AUTOSAR XML (schema 4-0-3)
package /ComponentTypes
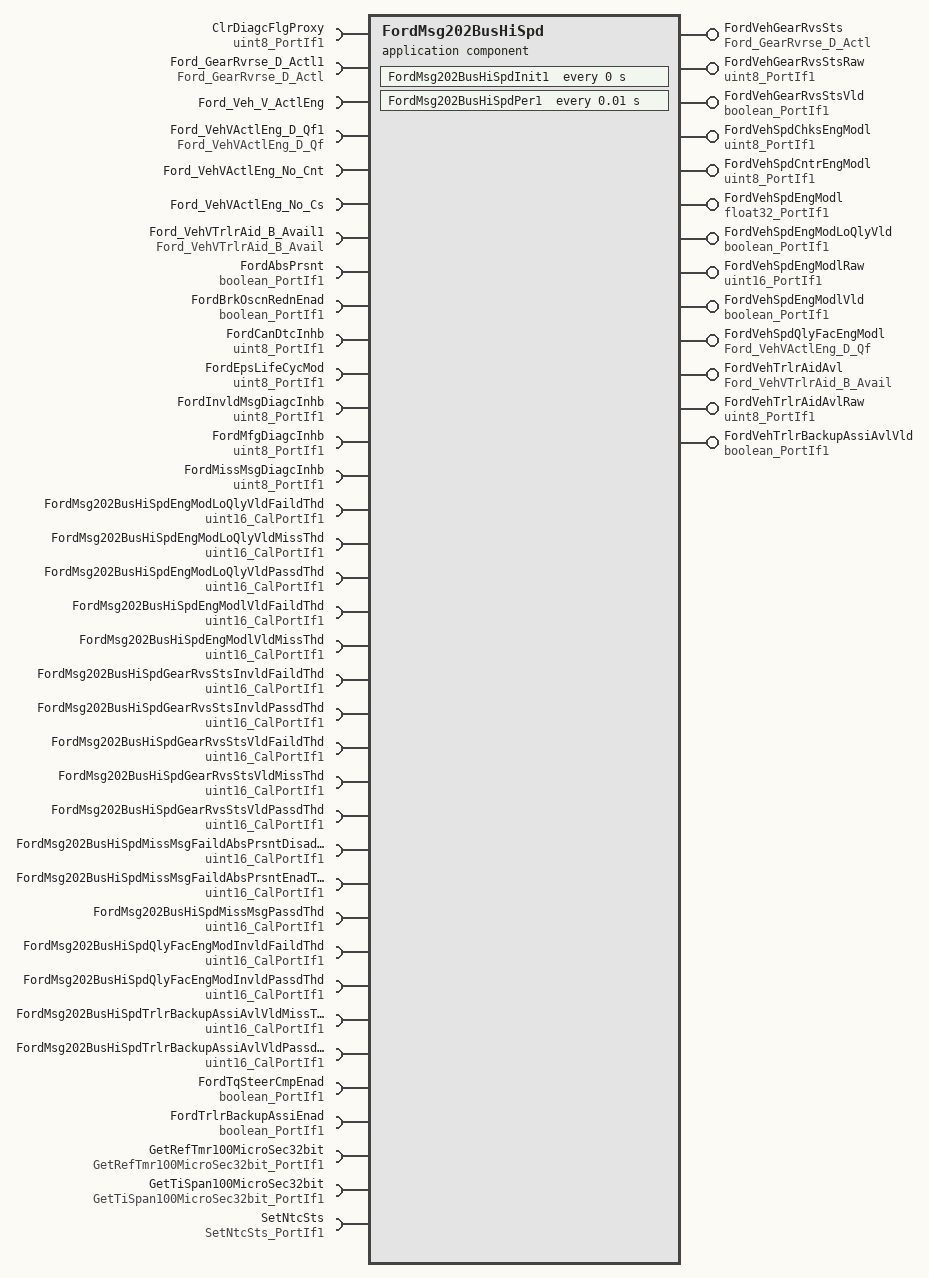
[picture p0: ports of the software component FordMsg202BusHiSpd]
  application sw component type FordMsg202BusHiSpd
    13 x provide port:
      FordVehGearRvsSts: nonqueued-sender-com-spec{data-element=Ford_GearRvrse_D_Actl, init-value=7}, provided-interface=Ford_GearRvrse_D_Actl
      FordVehGearRvsStsRaw: nonqueued-sender-com-spec{data-element=Val, init-value=7}, provided-interface=uint8_PortIf1
      FordVehGearRvsStsVld: nonqueued-sender-com-spec{data-element=Logl, init-value=0}, provided-interface=boolean_PortIf1
      FordVehSpdChksEngModl: nonqueued-sender-com-spec{data-element=Val, init-value=0}, provided-interface=uint8_PortIf1
      FordVehSpdCntrEngModl: nonqueued-sender-com-spec{data-element=Val, init-value=0}, provided-interface=uint8_PortIf1
      FordVehSpdEngModl: nonqueued-sender-com-spec{data-element=Val, init-value=0}, provided-interface=float32_PortIf1
      FordVehSpdEngModLoQlyVld: nonqueued-sender-com-spec{data-element=Logl, init-value=0}, provided-interface=boolean_PortIf1
      FordVehSpdEngModlRaw: nonqueued-sender-com-spec{data-element=Val, init-value=0}, provided-interface=uint16_PortIf1
      FordVehSpdEngModlVld: nonqueued-sender-com-spec{data-element=Logl, init-value=0}, provided-interface=boolean_PortIf1
      FordVehSpdQlyFacEngModl: nonqueued-sender-com-spec{data-element=Ford_VehVActlEng_D_Qf, init-value=0}, provided-interface=Ford_VehVActlEng_D_Qf
      FordVehTrlrAidAvl: nonqueued-sender-com-spec{data-element=Ford_VehVTrlrAid_B_Avail, init-value=0}, provided-interface=Ford_VehVTrlrAid_B_Avail
      FordVehTrlrAidAvlRaw: nonqueued-sender-com-spec{data-element=Val, init-value=0}, provided-interface=uint8_PortIf1
      FordVehTrlrBackupAssiAvlVld: nonqueued-sender-com-spec{data-element=Logl, init-value=0}, provided-interface=boolean_PortIf1
    36 x require port:
      ClrDiagcFlgProxy: nonqueued-receiver-com-spec{data-element=Val, filter=data-filter-type=ALWAYS, init-value=0}, required-interface=uint8_PortIf1
      Ford_GearRvrse_D_Actl1: nonqueued-receiver-com-spec{data-element=Ford_GearRvrse_D_Actl, filter=data-filter-type=ALWAYS, init-value=7}, required-interface=Ford_GearRvrse_D_Actl
      Ford_Veh_V_ActlEng: nonqueued-receiver-com-spec{data-element=Ford_Veh_V_ActlEng, filter=data-filter-type=ALWAYS, init-value=0}, required-interface=Ford_Veh_V_ActlEng
      Ford_VehVActlEng_D_Qf1: nonqueued-receiver-com-spec{data-element=Ford_VehVActlEng_D_Qf, filter=data-filter-type=ALWAYS, init-value=0}, required-interface=Ford_VehVActlEng_D_Qf
      Ford_VehVActlEng_No_Cnt: nonqueued-receiver-com-spec{data-element=Ford_VehVActlEng_No_Cnt, filter=data-filter-type=ALWAYS, init-value=0}, required-interface=Ford_VehVActlEng_No_Cnt
      Ford_VehVActlEng_No_Cs: nonqueued-receiver-com-spec{data-element=Ford_VehVActlEng_No_Cs, filter=data-filter-type=ALWAYS, init-value=0}, required-interface=Ford_VehVActlEng_No_Cs
      Ford_VehVTrlrAid_B_Avail1: nonqueued-receiver-com-spec{data-element=Ford_VehVTrlrAid_B_Avail, filter=data-filter-type=ALWAYS, init-value=0}, required-interface=Ford_VehVTrlrAid_B_Avail
      FordAbsPrsnt: nonqueued-receiver-com-spec{data-element=Logl, filter=data-filter-type=ALWAYS, init-value=0}, required-interface=boolean_PortIf1
      FordBrkOscnRednEnad: nonqueued-receiver-com-spec{data-element=Logl, filter=data-filter-type=ALWAYS, init-value=0}, required-interface=boolean_PortIf1
      FordCanDtcInhb: nonqueued-receiver-com-spec{data-element=Val, filter=data-filter-type=ALWAYS, init-value=1}, required-interface=uint8_PortIf1
      FordEpsLifeCycMod: nonqueued-receiver-com-spec{data-element=Val, filter=data-filter-type=ALWAYS, init-value=0}, required-interface=uint8_PortIf1
      FordInvldMsgDiagcInhb: nonqueued-receiver-com-spec{data-element=Val, filter=data-filter-type=ALWAYS, init-value=0}, required-interface=uint8_PortIf1
      FordMfgDiagcInhb: nonqueued-receiver-com-spec{data-element=Val, filter=data-filter-type=ALWAYS, init-value=0}, required-interface=uint8_PortIf1
      FordMissMsgDiagcInhb: nonqueued-receiver-com-spec{data-element=Val, filter=data-filter-type=ALWAYS, init-value=0}, required-interface=uint8_PortIf1
      FordMsg202BusHiSpdEngModLoQlyVldFaildThd: parameter-require-com-spec{init-value=0, parameter=Val}, required-interface=uint16_CalPortIf1
      FordMsg202BusHiSpdEngModLoQlyVldMissThd: parameter-require-com-spec{init-value=100, parameter=Val}, required-interface=uint16_CalPortIf1
      FordMsg202BusHiSpdEngModLoQlyVldPassdThd: parameter-require-com-spec{init-value=0, parameter=Val}, required-interface=uint16_CalPortIf1
      FordMsg202BusHiSpdEngModlVldFaildThd: parameter-require-com-spec{init-value=0, parameter=Val}, required-interface=uint16_CalPortIf1
      FordMsg202BusHiSpdEngModlVldMissThd: parameter-require-com-spec{init-value=100, parameter=Val}, required-interface=uint16_CalPortIf1
      FordMsg202BusHiSpdGearRvsStsInvldFaildThd: parameter-require-com-spec{init-value=0, parameter=Val}, required-interface=uint16_CalPortIf1
      FordMsg202BusHiSpdGearRvsStsInvldPassdThd: parameter-require-com-spec{init-value=0, parameter=Val}, required-interface=uint16_CalPortIf1
      FordMsg202BusHiSpdGearRvsStsVldFaildThd: parameter-require-com-spec{init-value=0, parameter=Val}, required-interface=uint16_CalPortIf1
      FordMsg202BusHiSpdGearRvsStsVldMissThd: parameter-require-com-spec{init-value=100, parameter=Val}, required-interface=uint16_CalPortIf1
      FordMsg202BusHiSpdGearRvsStsVldPassdThd: parameter-require-com-spec{init-value=0, parameter=Val}, required-interface=uint16_CalPortIf1
      FordMsg202BusHiSpdMissMsgFaildAbsPrsntDisadThd: parameter-require-com-spec{init-value=100, parameter=Val}, required-interface=uint16_CalPortIf1
      FordMsg202BusHiSpdMissMsgFaildAbsPrsntEnadThd: parameter-require-com-spec{init-value=100, parameter=Val}, required-interface=uint16_CalPortIf1
      FordMsg202BusHiSpdMissMsgPassdThd: parameter-require-com-spec{init-value=100, parameter=Val}, required-interface=uint16_CalPortIf1
      FordMsg202BusHiSpdQlyFacEngModInvldFaildThd: parameter-require-com-spec{init-value=0, parameter=Val}, required-interface=uint16_CalPortIf1
      FordMsg202BusHiSpdQlyFacEngModInvldPassdThd: parameter-require-com-spec{init-value=0, parameter=Val}, required-interface=uint16_CalPortIf1
      FordMsg202BusHiSpdTrlrBackupAssiAvlVldMissThd: parameter-require-com-spec{init-value=100, parameter=Val}, required-interface=uint16_CalPortIf1
      FordMsg202BusHiSpdTrlrBackupAssiAvlVldPassdThd: parameter-require-com-spec{init-value=0, parameter=Val}, required-interface=uint16_CalPortIf1
      FordTqSteerCmpEnad: nonqueued-receiver-com-spec{data-element=Logl, filter=data-filter-type=ALWAYS, init-value=0}, required-interface=boolean_PortIf1
      FordTrlrBackupAssiEnad: nonqueued-receiver-com-spec{data-element=Logl, filter=data-filter-type=ALWAYS, init-value=0}, required-interface=boolean_PortIf1
      GetRefTmr100MicroSec32bit: client-com-spec=Oper, required-interface=GetRefTmr100MicroSec32bit_PortIf1
      GetTiSpan100MicroSec32bit: client-com-spec=Oper, required-interface=GetTiSpan100MicroSec32bit_PortIf1
      SetNtcSts: client-com-spec=Oper, required-interface=SetNtcSts_PortIf1
    behavior FordMsg202BusHiSpd_InternalBehavior
      ar-typed-per-instance-memorys:
        33 x data, all with sw-calibration-access=READ-ONLY:
          ClrDiagcFlgProxyPrev: type=uint8
          FirstTranVldFlg: type=boolean
          FordVehGearRvsStsInvldFaildRefTi: type=uint32
          FordVehGearRvsStsInvldPassdRefTi: type=uint32
          FordVehGearRvsStsPrev: type=Ford_GearRvrse_D_Actl
          FordVehGearRvsStsRawPrev: type=uint8
          FordVehGearRvsStsVldFaildRefTi: type=uint32
          FordVehGearRvsStsVldMissRefTi: type=uint32
          FordVehGearRvsStsVldPassdRefTi: type=uint32
          FordVehGearRvsStsVldPrev: type=boolean
          FordVehMsg202Miss: type=boolean
          FordVehMsg202Rxd: type=boolean
          FordVehSpdChksEngModlPrev: type=uint8
          FordVehSpdCntrEngModlPrev: type=uint8
          FordVehSpdEngModLoQlyVldFaildRefTi: type=uint32
          FordVehSpdEngModLoQlyVldMissRefTi: type=uint32
          FordVehSpdEngModLoQlyVldPassdRefTi: type=uint32
          FordVehSpdEngModLoQlyVldPrev: type=boolean
          FordVehSpdEngModlPrev: type=float32
          FordVehSpdEngModlRawPrev: type=uint16
          FordVehSpdEngModlVldFaildRefTi: type=uint32
          FordVehSpdEngModlVldMissRefTi: type=uint32
          FordVehSpdEngModlVldPrev: type=boolean
          FordVehSpdQlyFacEngModlInvldFaildRefTi: type=uint32
          FordVehSpdQlyFacEngModlInvldPassdRefTi: type=uint32
          FordVehSpdQlyFacEngModlPrev: type=Ford_VehVActlEng_D_Qf
          FordVehTrlrAidAvlPrev: type=Ford_VehVTrlrAid_B_Avail
          FordVehTrlrAidAvlRawPrev: type=uint8
          FordVehTrlrBackupAssiAvlVldMissRefTi: type=uint32
          FordVehTrlrBackupAssiAvlVldPassdRefTi: type=uint32
          FordVehTrlrBackupAssiAvlVldPrev: type=boolean
          MissMsgFaildRefTi: type=uint32
          MissMsgPassdRefTi: type=uint32
      timing event FordMsg202BusHiSpd_InitEvent: start-on-event=FordMsg202BusHiSpdInit1, period=0
      timing event TMT_FordMsg202BusHiSpdPer1: start-on-event=FordMsg202BusHiSpdPer1, period=0.01
      port-api-options:
        enable-take-address=false, indirect-api=false, port=Ford_Veh_V_ActlEng
        enable-take-address=false, indirect-api=false, port=Ford_VehVActlEng_No_Cnt
        enable-take-address=false, indirect-api=false, port=Ford_VehVActlEng_No_Cs
        enable-take-address=false, indirect-api=false, port=FordBrkOscnRednEnad
        enable-take-address=false, indirect-api=false, port=FordMsg202BusHiSpdEngModLoQlyVldMissThd
        enable-take-address=false, indirect-api=false, port=FordMsg202BusHiSpdEngModLoQlyVldPassdThd
        enable-take-address=false, indirect-api=false, port=FordMsg202BusHiSpdQlyFacEngModInvldPassdThd
        enable-take-address=false, indirect-api=false, port=FordVehSpdEngModlVld
        enable-take-address=false, indirect-api=false, port=FordVehSpdQlyFacEngModl
        enable-take-address=false, indirect-api=false, port=GetRefTmr100MicroSec32bit
      runnable FordMsg202BusHiSpdInit1
        sync call SC_GetRefTmr100MicroSec32bit_Oper: operation=GetRefTmr100MicroSec32bit.Oper, timeout=0
      runnable FordMsg202BusHiSpdPer1
        data-receive-point-by-arguments:
          16 x access:
            REC_ClrDiagcFlgProxy_Val: accessed-variable=ClrDiagcFlgProxy.Val
            REC_Ford_GearRvrse_D_Actl1_Ford_GearRvrse_D_Actl: accessed-variable=Ford_GearRvrse_D_Actl1.Ford_GearRvrse_D_Actl
            REC_Ford_Veh_V_ActlEng_Ford_Veh_V_ActlEng: accessed-variable=Ford_Veh_V_ActlEng.Ford_Veh_V_ActlEng
            REC_Ford_VehVActlEng_D_Qf1_Ford_VehVActlEng_D_Qf: accessed-variable=Ford_VehVActlEng_D_Qf1.Ford_VehVActlEng_D_Qf
            REC_Ford_VehVActlEng_No_Cnt_Ford_VehVActlEng_No_Cnt: accessed-variable=Ford_VehVActlEng_No_Cnt.Ford_VehVActlEng_No_Cnt
            REC_Ford_VehVActlEng_No_Cs_Ford_VehVActlEng_No_Cs: accessed-variable=Ford_VehVActlEng_No_Cs.Ford_VehVActlEng_No_Cs
            REC_Ford_VehVTrlrAid_B_Avail1_Ford_VehVTrlrAid_B_Avail: accessed-variable=Ford_VehVTrlrAid_B_Avail1.Ford_VehVTrlrAid_B_Avail
            REC_FordAbsPrsnt_Logl: accessed-variable=FordAbsPrsnt.Logl
            REC_FordBrkOscnRednEnad_Logl: accessed-variable=FordBrkOscnRednEnad.Logl
            REC_FordCanDtcInhb_Val: accessed-variable=FordCanDtcInhb.Val
            REC_FordEpsLifeCycMod_Val: accessed-variable=FordEpsLifeCycMod.Val
            REC_FordInvldMsgDiagcInhb_Val: accessed-variable=FordInvldMsgDiagcInhb.Val
            REC_FordMfgDiagcInhb_Val: accessed-variable=FordMfgDiagcInhb.Val
            REC_FordMissMsgDiagcInhb_Val: accessed-variable=FordMissMsgDiagcInhb.Val
            REC_FordTqSteerCmpEnad_Logl: accessed-variable=FordTqSteerCmpEnad.Logl
            REC_FordTrlrBackupAssiEnad_Logl: accessed-variable=FordTrlrBackupAssiEnad.Logl
        data-send-points:
          13 x access:
            SEND_FordVehGearRvsSts_Ford_GearRvrse_D_Actl: accessed-variable=FordVehGearRvsSts.Ford_GearRvrse_D_Actl
            SEND_FordVehGearRvsStsRaw_Val: accessed-variable=FordVehGearRvsStsRaw.Val
            SEND_FordVehGearRvsStsVld_Logl: accessed-variable=FordVehGearRvsStsVld.Logl
            SEND_FordVehSpdChksEngModl_Val: accessed-variable=FordVehSpdChksEngModl.Val
            SEND_FordVehSpdCntrEngModl_Val: accessed-variable=FordVehSpdCntrEngModl.Val
            SEND_FordVehSpdEngModl_Val: accessed-variable=FordVehSpdEngModl.Val
            SEND_FordVehSpdEngModLoQlyVld_Logl: accessed-variable=FordVehSpdEngModLoQlyVld.Logl
            SEND_FordVehSpdEngModlRaw_Val: accessed-variable=FordVehSpdEngModlRaw.Val
            SEND_FordVehSpdEngModlVld_Logl: accessed-variable=FordVehSpdEngModlVld.Logl
            SEND_FordVehSpdQlyFacEngModl_Ford_VehVActlEng_D_Qf: accessed-variable=FordVehSpdQlyFacEngModl.Ford_VehVActlEng_D_Qf
            SEND_FordVehTrlrAidAvl_Ford_VehVTrlrAid_B_Avail: accessed-variable=FordVehTrlrAidAvl.Ford_VehVTrlrAid_B_Avail
            SEND_FordVehTrlrAidAvlRaw_Val: accessed-variable=FordVehTrlrAidAvlRaw.Val
            SEND_FordVehTrlrBackupAssiAvlVld_Logl: accessed-variable=FordVehTrlrBackupAssiAvlVld.Logl
        sync call SC_GetRefTmr100MicroSec32bit_Oper: operation=GetRefTmr100MicroSec32bit.Oper, timeout=0
        sync call SC_GetTiSpan100MicroSec32bit_Oper: operation=GetTiSpan100MicroSec32bit.Oper, timeout=0
        sync call SC_SetNtcSts_Oper: operation=SetNtcSts.Oper, timeout=0
  swc implementation FordMsg202BusHiSpd_Implementation: behavior=FordMsg202BusHiSpd_InternalBehavior
    code-descriptors:
      code Default: artifact-descriptors=autosar-engineering-object={short-label=Default, category=SWSRC}
